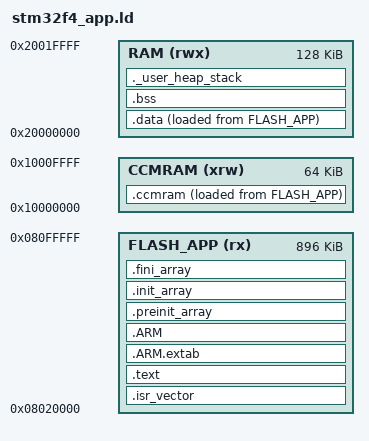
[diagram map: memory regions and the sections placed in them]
/*
 * STM32F4 Application Linker Script
 *
 * Application region starts at 0x08020000 (sector 5).
 */

MEMORY
{
    CCMRAM    (xrw) : ORIGIN = 0x10000000, LENGTH = 64K
    FLASH_APP (rx)  : ORIGIN = 0x08020000, LENGTH = 896K
    RAM       (rwx) : ORIGIN = 0x20000000, LENGTH = 128K
}

ENTRY(Reset_Handler)

_Min_Stack_Size = 0x00000400; /* 1KB */
_Min_Heap_Size  = 0x00000800; /* 2KB */

_estack = ORIGIN(RAM) + LENGTH(RAM);
PROVIDE(__StackTop = _estack);

SECTIONS
{
    /* Vector table */
    .isr_vector :
    {
        . = ALIGN(4);
        KEEP(*(.isr_vector))
        . = ALIGN(4);
    } > FLASH_APP

    /* Program code and read-only data */
    .text :
    {
        . = ALIGN(4);
        *(.text)
        *(.text*)
        *(.glue_7)
        *(.glue_7t)
        *(.rodata)
        *(.rodata*)

        KEEP (*(.init))
        KEEP (*(.fini))

        . = ALIGN(4);
        PROVIDE(__etext = .);
    } > FLASH_APP

    .ARM.extab :
    {
        . = ALIGN(4);
        *(.ARM.extab* .gnu.linkonce.armextab.*)
        . = ALIGN(4);
    } > FLASH_APP

    .ARM :
    {
        . = ALIGN(4);
        __exidx_start = .;
        *(.ARM.exidx*)
        __exidx_end = .;
        . = ALIGN(4);
    } > FLASH_APP

    .preinit_array :
    {
        . = ALIGN(4);
        PROVIDE_HIDDEN (__preinit_array_start = .);
        KEEP (*(.preinit_array*))
        PROVIDE_HIDDEN (__preinit_array_end = .);
        . = ALIGN(4);
    } > FLASH_APP

    .init_array :
    {
        . = ALIGN(4);
        PROVIDE_HIDDEN (__init_array_start = .);
        KEEP (*(SORT(.init_array.*)))
        KEEP (*(.init_array*))
        PROVIDE_HIDDEN (__init_array_end = .);
        . = ALIGN(4);
    } > FLASH_APP

    .fini_array :
    {
        . = ALIGN(4);
        PROVIDE_HIDDEN (__fini_array_start = .);
        KEEP (*(SORT(.fini_array.*)))
        KEEP (*(.fini_array*))
        PROVIDE_HIDDEN (__fini_array_end = .);
        . = ALIGN(4);
    } > FLASH_APP

    /* Used by the startup to initialize data */
    _sidata = LOADADDR(.data);

    /* Initialized data sections into RAM, load in FLASH_APP */
    .data :
    {
        . = ALIGN(4);
        _sdata = .;
        *(.data)
        *(.data*)
        . = ALIGN(4);
        _edata = .;
    } > RAM AT> FLASH_APP

    /* CCM-RAM section */
    _siccmram = LOADADDR(.ccmram);
    .ccmram :
    {
        . = ALIGN(4);
        _sccmram = .;
        *(.ccmram)
        *(.ccmram*)
        . = ALIGN(4);
        _eccmram = .;
    } > CCMRAM AT> FLASH_APP

    /* Uninitialized data */
    .bss :
    {
        . = ALIGN(4);
        _sbss = .;
        __bss_start__ = _sbss;
        *(.bss)
        *(.bss*)
        *(COMMON)
        . = ALIGN(4);
        _ebss = .;
        __bss_end__ = _ebss;
    } > RAM

    /* User heap and stack */
    ._user_heap_stack :
    {
        . = ALIGN(8);
        PROVIDE ( end = . );
        PROVIDE ( _end = . );
        . = . + _Min_Heap_Size;
        . = . + _Min_Stack_Size;
        . = ALIGN(8);
    } > RAM

    /* Remove unused library sections */
    /DISCARD/ :
    {
        libc.a ( * )
        libm.a ( * )
        libgcc.a ( * )
    }

    /* Provide runtime symbols */
    PROVIDE(_etext = __etext);
    PROVIDE(_sdata = _sdata);
    PROVIDE(_edata = _edata);
    PROVIDE(_sbss  = _sbss);
    PROVIDE(_ebss  = _ebss);
}

